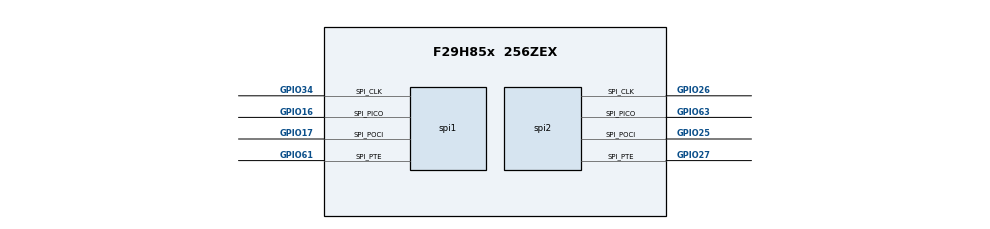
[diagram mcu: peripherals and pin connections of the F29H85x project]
/**
 * @cliArgs --device "F29H85x" --package "256ZEX" --part "F29H85x_256ZEX" --context "CPU1" --product "MCU_SDK_F29H85x@1.00.00.00"
 * @versions {"tool":"1.22.0+3877"}
 */

const divider15       = system.clockTree["PLL_REFDIV"];
divider15.divideValue = 1;

const multiplier1         = system.clockTree["PLL_IMULT"];
multiplier1.multiplyValue = 40;

const mux7       = system.clockTree["OSCCLKSRCSEL"];
mux7.inputSelect = "INTOSC2";

/**
 * Import the modules used in this configuration.
 */
const jtag  = scripting.addModule("/driverlib/jtag.js");
const spi   = scripting.addModule("/driverlib/spi.js", {}, false);
const spi1  = spi.addInstance();
const spi2  = spi.addInstance();

/**
 * Write custom configuration values to the imported modules.
 */
spi1.bitRate                   = 2000000;
spi1.txFifo                    = "SPI_FIFO_TX2";
spi1.rxFifo                    = "SPI_FIFO_RX2";
spi1.emulationMode             = "SPI_EMULATION_FREE_RUN";
spi1.$name                     = "SPIA_peripheral";
spi1.enabledFIFOInterrupts     = ["SPI_INT_RXFF"];
spi1.registerInterrupts        = true;
spi1.registerSpiTxInt          = false;
spi1.spi.$assign               = "SPIA";
spi1.spi.spi_picoPin.$assign   = "GPIO16";
spi1.spi.spi_pociPin.$assign   = "GPIO17";
spi1.spi.spi_clkPin.$assign    = "GPIO34";
spi1.spi.spi_ptePin.$assign    = "GPIO61";
spi1.periphClock.$name         = "driverlib_perClock0";
spi1.periphConfig.$name        = "driverlib_perConfig0";
spi1.spiRXInt.interruptHandler = "spiaRxFIFOISR";

spi2.bitRate                 = 2000000;
spi2.txFifo                  = "SPI_FIFO_TX2";
spi2.rxFifo                  = "SPI_FIFO_RX2";
spi2.emulationMode           = "SPI_EMULATION_FREE_RUN";
spi2.$name                   = "SPIB_controller";
spi2.enabledFIFOInterrupts   = ["SPI_INT_TXFF"];
spi2.mode                    = "SPI_MODE_CONTROLLER";
spi2.useInterrupts           = false;
spi2.spi.spi_picoPin.$assign = "GPIO63";
spi2.spi.spi_pociPin.$assign = "GPIO25";
spi2.spi.spi_clkPin.$assign  = "GPIO26";
spi2.spi.spi_ptePin.$assign  = "GPIO27";
spi2.periphClock.$name       = "driverlib_perClock1";
spi2.periphConfig.$name      = "driverlib_perConfig1";
